AUTOSAR XML (schema 4-0-3)
standard types defined: Boolean, UInt8
package /AUTOSAR_Platform/DataConstrs
  range DC_Boolean: raw 0..1
package /PATAC/MSM/ComponentTypes
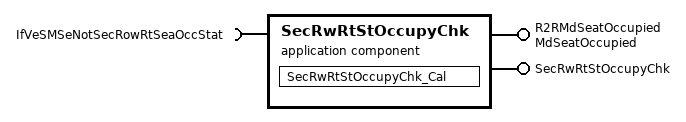
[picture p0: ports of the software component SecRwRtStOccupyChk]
  application sw component type SecRwRtStOccupyChk
    provide port R2RMdSeatOccupied: nonqueued-sender-com-spec{data-element=MdSeatOccupied/Val, init-value=0}, provided-interface=MdSeatOccupied
    provide port SecRwRtStOccupyChk: server-com-spec{operation=Cal, queue-length=1}, provided-interface=SecRwRtStOccupyChk
    require port IfVeSMSeNotSecRowRtSeaOccStat: nonqueued-receiver-com-spec{data-element=IfVeSMSeNotSecRowRtSeaOccStat/Val, filter=data-filter-type=ALWAYS, init-value=0}, required-interface=IfVeSMSeNotSecRowRtSeaOccStat
    behavior SecRwRtStOccupyChk_InternalBehavior
      operation invoked event OIT_SecRwRtStOccupyChk_Cal_SecRwRtStOccupyChk_Cal: start-on-event=SecRwRtStOccupyChk_Cal, operation=SecRwRtStOccupyChk.Cal
      runnable SecRwRtStOccupyChk_Cal
        data-receive-point-by-arguments:
          access REC_IfVeSMSeNotSecRowRtSeaOccStat_Val: accessed-variable=IfVeSMSeNotSecRowRtSeaOccStat.Val
        data-send-points:
          access SEND_R2RMdSeatOccupied_Val: accessed-variable=R2RMdSeatOccupied.Val
  swc implementation SecRwRtStOccupyChk_Implementation: behavior=SecRwRtStOccupyChk_InternalBehavior
    code-descriptors:
      code Default: artifact-descriptors=autosar-engineering-object={short-label=Default, category=SWSRC}
package /PATAC/MSM/ModeAdjust/DataType
  impl type SeatOccupiedSts1: category=VALUE, base-type=UInt8, sw-calibration-access=READ-ONLY, compu {0=SeatOccupiedSts_Unknown, 1=SeatOccupiedSts_Empty, 2=SeatOccupiedSts_Occupied, 3=SeatOccupiedSts_DataNotAvailable}, type-emitter=RTE
package /PATAC/MSM/ModeAdjust/Interfaces
  sender receiver interface IfVeSMSeNotSecRowRtSeaOccStat: invalidation-policy{data-element=IfVeSMSeNotSecRowRtSeaOccStat/Val, handle-invalid=DONT-INVALIDATE}
    data Val: type=SeatOccupiedSts1
package /PATAC/MSM/ModeAdjust/PortInterface
  client server interface SecRwRtStOccupyChk
    operation Cal
  sender receiver interface MdSeatOccupied: invalidation-policy{data-element=MdSeatOccupied/Val, handle-invalid=DONT-INVALIDATE}
    data Val: type=Boolean
